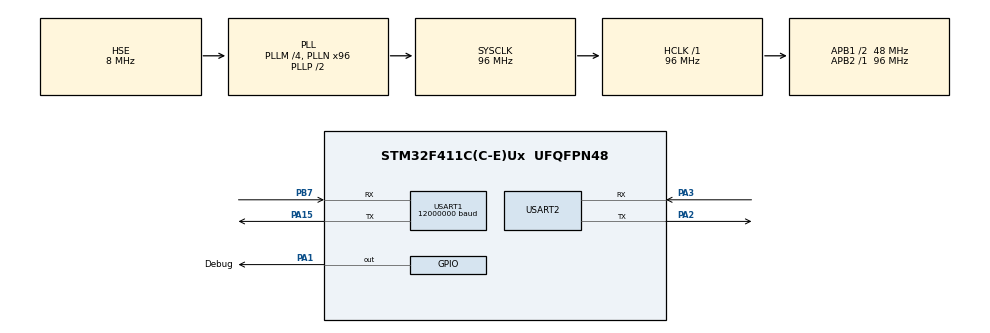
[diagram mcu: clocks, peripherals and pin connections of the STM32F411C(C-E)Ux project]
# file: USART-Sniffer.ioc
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Dma.Request0=USART1_RX
Dma.USART1_RX.0.Direction=DMA_PERIPH_TO_MEMORY
Dma.USART1_RX.0.FIFOMode=DMA_FIFOMODE_DISABLE
Dma.USART1_RX.0.Instance=DMA2_Stream2
Dma.USART1_RX.0.MemDataAlignment=DMA_MDATAALIGN_BYTE
Dma.USART1_RX.0.MemInc=DMA_MINC_ENABLE
Dma.USART1_RX.0.Mode=DMA_NORMAL
Dma.USART1_RX.0.PeriphDataAlignment=DMA_PDATAALIGN_BYTE
Dma.USART1_RX.0.PeriphInc=DMA_PINC_DISABLE
Dma.USART1_RX.0.Priority=DMA_PRIORITY_VERY_HIGH
Mcu.Family=STM32F4
Mcu.Name=STM32F411C(C-E)Ux
Mcu.Package=UFQFPN48
NVIC.DMA2_Stream2_IRQn=true\:0\:0\:false\:false\:true\:false\:true\:true
NVIC.PriorityGroup=NVIC_PRIORITYGROUP_4
NVIC.USART1_IRQn=true\:0\:0\:false\:false\:true\:true\:true\:true
PA1.GPIO_Label=Debug
PA1.Signal=GPIO_Output
PA15.Mode=Asynchronous
PA15.Signal=USART1_TX
PA2.Mode=Asynchronous
PA2.Signal=USART2_TX
PA3.Mode=Asynchronous
PA3.Signal=USART2_RX
PB7.Mode=Asynchronous
PB7.Signal=USART1_RX
PH0\ -\ OSC_IN.Mode=HSE-External-Oscillator
PH0\ -\ OSC_IN.Signal=RCC_OSC_IN
PH1\ -\ OSC_OUT.Mode=HSE-External-Oscillator
PH1\ -\ OSC_OUT.Signal=RCC_OSC_OUT
ProjectManager.HeapSize=0x200
ProjectManager.StackSize=0x400
ProjectManager.TargetToolchain=STM32CubeIDE
RCC.48MHZClocksFreq_Value=48000000
RCC.AHBFreq_Value=96000000
RCC.APB1CLKDivider=RCC_HCLK_DIV2
RCC.APB1Freq_Value=48000000
RCC.APB1TimFreq_Value=96000000
RCC.APB2Freq_Value=96000000
RCC.APB2TimFreq_Value=96000000
RCC.CortexFreq_Value=96000000
RCC.HCLKFreq_Value=96000000
RCC.HSE_VALUE=8000000
RCC.HSI_VALUE=16000000
RCC.LSE_VALUE=32768
RCC.PLLM=4
RCC.PLLN=96
RCC.PLLSourceVirtual=RCC_PLLSOURCE_HSE
RCC.SYSCLKFreq_VALUE=96000000
RCC.SYSCLKSource=RCC_SYSCLKSOURCE_PLLCLK
RCC.VCOOutputFreq_Value=192000000
USART1.BaudRate=12000000
USART1.Mode=MODE_RX
USART1.OverSampling=UART_OVERSAMPLING_8
USART1.VirtualMode=VM_ASYNC
USART2.VirtualMode=VM_ASYNC
board=custom

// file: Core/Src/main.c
/* USER CODE BEGIN Header */
/**
  ******************************************************************************
  * @file           : main.c
  * @brief          : Main program body
  ******************************************************************************
  * @attention
  *
  * Copyright (c) 2023 STMicroelectronics.
  * All rights reserved.
  *
  * This software is licensed under terms that can be found in the LICENSE file
  * in the root directory of this software component.
  * If no LICENSE file comes with this software, it is provided AS-IS.
  *
  ******************************************************************************
  */
/* USER CODE END Header */
#include "main.h"

/* USER CODE BEGIN Includes */
#include "stdbool.h"
/* USER CODE END Includes */

/* USER CODE BEGIN PD */
#define UART_TX_PERIOD			250
/* USER CODE END PD */

UART_HandleTypeDef huart1;
UART_HandleTypeDef huart2;
DMA_HandleTypeDef hdma_usart1_rx;

/* USER CODE BEGIN PV */
uint8_t UART_DataTX[USART_BUFFER_LEN];
uint8_t UART_DataRX[USART_BUFFER_LEN];
uint32_t TimeoutCounter = 0;
HAL_UART_StateTypeDef UARTStatus;
uint16_t ByteCounter = 0;
/* USER CODE END PV */

void SystemClock_Config(void);
static void MX_GPIO_Init(void);
static void MX_DMA_Init(void);
static void MX_USART1_UART_Init(void);
static void MX_USART2_UART_Init(void);

/* USER CODE BEGIN 0 */
uint8_t Data[2];
/* USER CODE END 0 */

int main(void)
{

  /* MCU Configuration--------------------------------------------------------*/

  /* Reset of all peripherals, Initializes the Flash interface and the Systick. */
  HAL_Init();

  /* Configure the system clock */
  SystemClock_Config();

  /* Initialize all configured peripherals */
  MX_GPIO_Init();
  MX_DMA_Init();
  MX_USART1_UART_Init();
  MX_USART2_UART_Init();
  /* USER CODE BEGIN 2 */

  HAL_UART_Receive_DMA(&huart1, Data, 2);

  /* USER CODE END 2 */

  /* Infinite loop */
  while (1)
  {

  }
}

void SystemClock_Config(void)
{
  RCC_OscInitTypeDef RCC_OscInitStruct = {0};
  RCC_ClkInitTypeDef RCC_ClkInitStruct = {0};

  /** Configure the main internal regulator output voltage
  */
  __HAL_RCC_PWR_CLK_ENABLE();
  __HAL_PWR_VOLTAGESCALING_CONFIG(PWR_REGULATOR_VOLTAGE_SCALE1);

  /** Initializes the RCC Oscillators according to the specified parameters
  * in the RCC_OscInitTypeDef structure.
  */
  RCC_OscInitStruct.OscillatorType = RCC_OSCILLATORTYPE_HSE;
  RCC_OscInitStruct.HSEState = RCC_HSE_ON;
  RCC_OscInitStruct.PLL.PLLState = RCC_PLL_ON;
  RCC_OscInitStruct.PLL.PLLSource = RCC_PLLSOURCE_HSE;
  RCC_OscInitStruct.PLL.PLLM = 4;
  RCC_OscInitStruct.PLL.PLLN = 96;
  RCC_OscInitStruct.PLL.PLLP = RCC_PLLP_DIV2;
  RCC_OscInitStruct.PLL.PLLQ = 4;
  if (HAL_RCC_OscConfig(&RCC_OscInitStruct) != HAL_OK)
  {
    Error_Handler();
  }

  /** Initializes the CPU, AHB and APB buses clocks
  */
  RCC_ClkInitStruct.ClockType = RCC_CLOCKTYPE_HCLK|RCC_CLOCKTYPE_SYSCLK
                              |RCC_CLOCKTYPE_PCLK1|RCC_CLOCKTYPE_PCLK2;
  RCC_ClkInitStruct.SYSCLKSource = RCC_SYSCLKSOURCE_PLLCLK;
  RCC_ClkInitStruct.AHBCLKDivider = RCC_SYSCLK_DIV1;
  RCC_ClkInitStruct.APB1CLKDivider = RCC_HCLK_DIV2;
  RCC_ClkInitStruct.APB2CLKDivider = RCC_HCLK_DIV1;

  if (HAL_RCC_ClockConfig(&RCC_ClkInitStruct, FLASH_LATENCY_3) != HAL_OK)
  {
    Error_Handler();
  }
}

static void MX_USART1_UART_Init(void)
{

  huart1.Instance = USART1;
  huart1.Init.BaudRate = 12000000;
  huart1.Init.WordLength = UART_WORDLENGTH_8B;
  huart1.Init.StopBits = UART_STOPBITS_1;
  huart1.Init.Parity = UART_PARITY_NONE;
  huart1.Init.Mode = UART_MODE_RX;
  huart1.Init.HwFlowCtl = UART_HWCONTROL_NONE;
  huart1.Init.OverSampling = UART_OVERSAMPLING_8;
  if (HAL_UART_Init(&huart1) != HAL_OK)
  {
    Error_Handler();
  }

}

static void MX_USART2_UART_Init(void)
{

  huart2.Instance = USART2;
  huart2.Init.BaudRate = 115200;
  huart2.Init.WordLength = UART_WORDLENGTH_8B;
  huart2.Init.StopBits = UART_STOPBITS_1;
  huart2.Init.Parity = UART_PARITY_NONE;
  huart2.Init.Mode = UART_MODE_TX_RX;
  huart2.Init.HwFlowCtl = UART_HWCONTROL_NONE;
  huart2.Init.OverSampling = UART_OVERSAMPLING_16;
  if (HAL_UART_Init(&huart2) != HAL_OK)
  {
    Error_Handler();
  }

}

static void MX_DMA_Init(void)
{

  /* DMA controller clock enable */
  __HAL_RCC_DMA2_CLK_ENABLE();

  /* DMA interrupt init */
  /* DMA2_Stream2_IRQn interrupt configuration */
  HAL_NVIC_SetPriority(DMA2_Stream2_IRQn, 0, 0);
  HAL_NVIC_EnableIRQ(DMA2_Stream2_IRQn);

}

static void MX_GPIO_Init(void)
{
  GPIO_InitTypeDef GPIO_InitStruct = {0};

  /* GPIO Ports Clock Enable */
  __HAL_RCC_GPIOH_CLK_ENABLE();
  __HAL_RCC_GPIOA_CLK_ENABLE();
  __HAL_RCC_GPIOB_CLK_ENABLE();

  /*Configure GPIO pin Output Level */
  HAL_GPIO_WritePin(Debug_GPIO_Port, Debug_Pin, GPIO_PIN_SET);

  /*Configure GPIO pin : Debug_Pin */
  GPIO_InitStruct.Pin = Debug_Pin;
  GPIO_InitStruct.Mode = GPIO_MODE_OUTPUT_PP;
  GPIO_InitStruct.Pull = GPIO_NOPULL;
  GPIO_InitStruct.Speed = GPIO_SPEED_FREQ_LOW;
  HAL_GPIO_Init(Debug_GPIO_Port, &GPIO_InitStruct);

}

/* USER CODE BEGIN 4 */

void HAL_GPIO_EXTI_Callback(uint16_t GPIO_Pin)
{

}

void HAL_UART_RxCpltCallback(UART_HandleTypeDef *huart)
{
	Debug_GPIO_Port->BSRR |= Debug_Pin << 16;
	Debug_GPIO_Port->BSRR |= Debug_Pin;

	HAL_UART_Receive_DMA(&huart1, Data, 2);
}

/* USER CODE END 4 */

void Error_Handler(void)
{
  __disable_irq();
  while (1)
  {
  }
}
